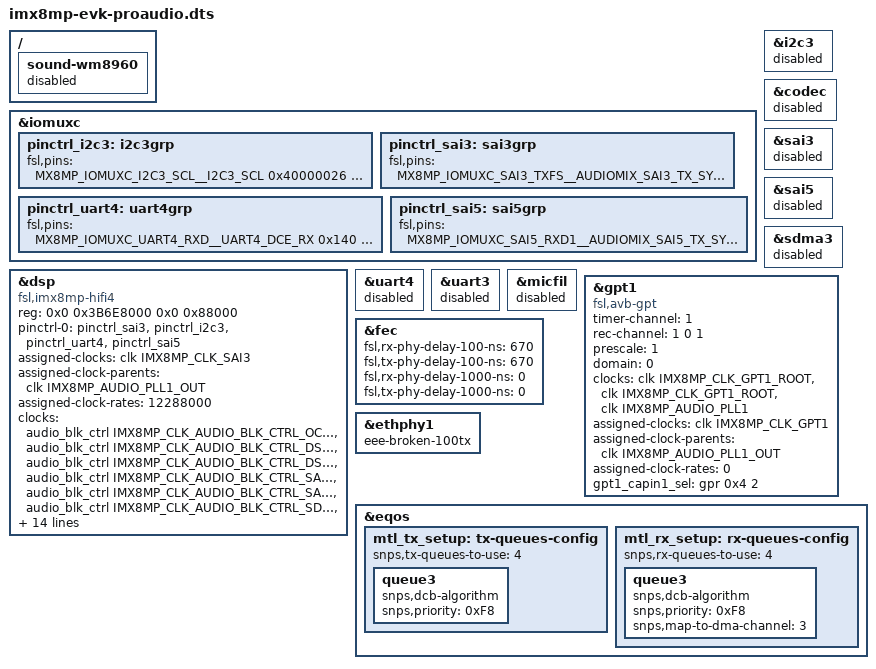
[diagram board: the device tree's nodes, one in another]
// SPDX-License-Identifier: GPL-2.0+
// Copyright NXP 2021

#include "imx8mp-evk.dts"

/ {
	sound-wm8960 {
		status = "disabled";
	};
};

&iomuxc {
	pinctrl_i2c3: i2c3grp {
		fsl,pins = <
			MX8MP_IOMUXC_I2C3_SCL__I2C3_SCL		0x40000026
			MX8MP_IOMUXC_I2C3_SDA__I2C3_SDA		0x40000026
		>;
	};

	pinctrl_sai3: sai3grp {
		fsl,pins = <
			MX8MP_IOMUXC_SAI3_TXFS__AUDIOMIX_SAI3_TX_SYNC	0xd6
			MX8MP_IOMUXC_SAI3_TXC__AUDIOMIX_SAI3_TX_BCLK	0xd6
			MX8MP_IOMUXC_SAI3_RXD__AUDIOMIX_SAI3_RX_DATA00	0xd6
			MX8MP_IOMUXC_SAI3_TXD__AUDIOMIX_SAI3_TX_DATA00	0xd6
			MX8MP_IOMUXC_SAI3_MCLK__AUDIOMIX_SAI3_MCLK	0xd6
			MX8MP_IOMUXC_SAI3_RXFS__GPIO4_IO28		0xd6
			MX8MP_IOMUXC_SAI3_RXC__GPIO4_IO29		0xd6
		>;
	};

	pinctrl_uart4: uart4grp {
		fsl,pins = <
			MX8MP_IOMUXC_UART4_RXD__UART4_DCE_RX    0x140
			MX8MP_IOMUXC_UART4_TXD__UART4_DCE_TX    0x140
		>;
	};
	pinctrl_sai5: sai5grp {
		fsl,pins = <
			MX8MP_IOMUXC_SAI5_RXD1__AUDIOMIX_SAI5_TX_SYNC	0xd6
			MX8MP_IOMUXC_SAI5_RXD2__AUDIOMIX_SAI5_TX_BCLK	0xd6
			MX8MP_IOMUXC_SAI5_RXD3__AUDIOMIX_SAI5_TX_DATA00	0xd6
			MX8MP_IOMUXC_SAI5_RXD0__AUDIOMIX_SAI5_RX_DATA00	0xd6
		>;
	};
};

&dsp {
	compatible = "fsl,imx8mp-hifi4";
	reg = <0x0 0x3B6E8000 0x0 0x88000>;
	pinctrl-names = "default";
	pinctrl-0 = <&pinctrl_sai3>, <&pinctrl_i2c3>, <&pinctrl_uart4>, <&pinctrl_sai5>;
	assigned-clocks = <&clk IMX8MP_CLK_SAI3>;
	assigned-clock-parents = <&clk IMX8MP_AUDIO_PLL1_OUT>;
	assigned-clock-rates = <12288000>;
	clocks = <&audio_blk_ctrl IMX8MP_CLK_AUDIO_BLK_CTRL_OCRAMA_IPG>,
			 <&audio_blk_ctrl IMX8MP_CLK_AUDIO_BLK_CTRL_DSP_ROOT>,
			 <&audio_blk_ctrl IMX8MP_CLK_AUDIO_BLK_CTRL_DSPDBG_ROOT>,
			 <&audio_blk_ctrl IMX8MP_CLK_AUDIO_BLK_CTRL_SAI3_IPG>,
			 <&audio_blk_ctrl IMX8MP_CLK_AUDIO_BLK_CTRL_SAI3_MCLK1>,
			 <&audio_blk_ctrl IMX8MP_CLK_AUDIO_BLK_CTRL_SDMA3_ROOT>,
			 <&clk IMX8MP_CLK_I2C3_ROOT>,
			 <&audio_blk_ctrl IMX8MP_CLK_AUDIO_BLK_CTRL_ASRC_IPG>,
			 <&audio_blk_ctrl IMX8MP_CLK_AUDIO_BLK_CTRL_SAI3_MCLK1>,
			 <&clk IMX8MP_CLK_UART4_ROOT>,
			 <&audio_blk_ctrl IMX8MP_CLK_AUDIO_BLK_CTRL_SAI5_IPG>,
			 <&audio_blk_ctrl IMX8MP_CLK_AUDIO_BLK_CTRL_SAI5_MCLK1>;
	clock-names = "ocram", "core", "debug",
				  "per_clk1", "per_clk2", "per_clk3", "per_clk4", "per_clk5", "per_clk6",
				  "per_clk7", "per_clk8", "per_clk9";
	firmware-name = "imx/dsp/hifi4.bin";
	power-domains = <&audiomix_pd>;
	mbox-names = "tx0", "rx0", "rxdb0";
	mboxes = <&mu2 0 0>,
			 <&mu2 1 0>,
			 <&mu2 3 0>;
	memory-region = <&dsp_vdev0buffer>, <&dsp_vdev0vring0>,
					<&dsp_vdev0vring1>, <&dsp_reserved>;
	syscon = <&audio_blk_ctrl>;
	status = "okay";
};

&i2c3 {
	status = "disabled";
};

&codec {
	status = "disabled";
};

&sai3 {
	status = "disabled";
};

&sai5 {
	status = "disabled";
};

&sdma3 {
	status = "disabled";
};

&uart4 {
	status = "disabled";
};

&uart3 {
	status = "disabled";
};

&micfil {
	status = "disabled";
};

/* AVB HW timer*/
&gpt1 {
	compatible = "fsl,avb-gpt";
	timer-channel = <1>; /* Use output compare channel 1*/
	rec-channel = <1 0 1>; // capture channel, eth port, ENET TC id
	prescale = <1>;
	domain = <0>;

	clocks = <&clk IMX8MP_CLK_GPT1_ROOT>,
		 <&clk IMX8MP_CLK_GPT1_ROOT>,
		 <&clk IMX8MP_AUDIO_PLL1>;
	clock-names = "ipg", "per", "audio_pll";

	/* Make the GPT clk root derive from the audio PLL*/
	assigned-clocks = <&clk IMX8MP_CLK_GPT1>;
	assigned-clock-parents = <&clk IMX8MP_AUDIO_PLL1_OUT>;
	assigned-clock-rates = <0>;

	gpt1_capin1_sel = <&gpr 0x4 2>;

	status = "okay";
};

&fec {
       fsl,rx-phy-delay-100-ns = <670>;
       fsl,tx-phy-delay-100-ns = <670>;
       fsl,rx-phy-delay-1000-ns = <0>;
       fsl,tx-phy-delay-1000-ns = <0>;
};

&ethphy1 {
	eee-broken-100tx;
};

&eqos {
    mtl_tx_setup: tx-queues-config {
        snps,tx-queues-to-use = <4>; // Reduced to 4
        /delete-node/ queue4;

        queue3 {
            snps,dcb-algorithm;
            snps,priority = <0xF8>; // Bitmask for priorities 4, 5, 6, and 7
        };
    };

    mtl_rx_setup: rx-queues-config {
        snps,rx-queues-to-use = <4>; // Reduced to 4
        /delete-node/ queue4;

        queue3 {
            snps,dcb-algorithm;
            snps,priority = <0xF8>; // Bitmask for priorities 4, 5, 6, and 7
            snps,map-to-dma-channel = <3>;
        };
    };
};
